AUTOSAR XML (schema 00048)
package /SecurityArchitecture/ComponentTypes
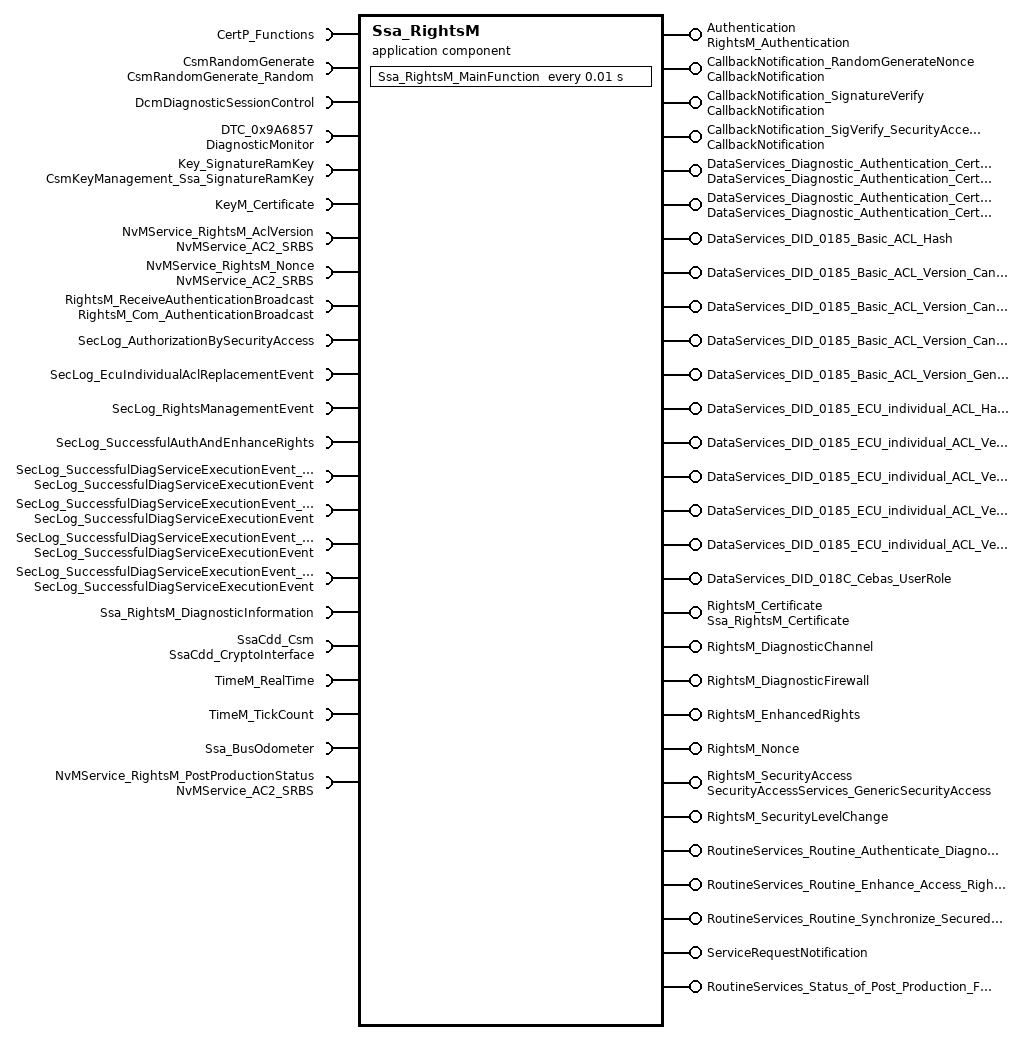
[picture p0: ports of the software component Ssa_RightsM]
  application sw component type Ssa_RightsM  # Handles a received diagnostic authentication broadcast and enters authenticated state if valid. Called by Ssa_BcTp whenever a Diagnostic Authentication broadcast message is received.
    28 x provide port:
      Authentication: mode-switch-sender-com-spec{mode-group=Mode, queue-length=1}, provided-interface=RightsM_Authentication
      CallbackNotification_RandomGenerateNonce: server-com-spec{operation=CallbackNotification, queue-length=1}, provided-interface=CallbackNotification  # Callback notification from the CSM random generate job. Configuration Variant(s): Asynchronous job processing.
      CallbackNotification_SignatureVerify: server-com-spec{operation=CallbackNotification, queue-length=1}, provided-interface=CallbackNotification  # Callback notification from the CSM signature verification job used for verifying the proof of ownership during diagnostic tester authentication. Configuration Variant(s): Asynchronous job processing.
      CallbackNotification_SigVerify_SecurityAccess: server-com-spec{operation=CallbackNotification, queue-length=1}, provided-interface=CallbackNotification  # Callback notification from the CSM signature verification job used for the security access. Configuration Variant(s): Asynchronous job processing.
      DataServices_Diagnostic_Authentication_Certificate_Identification_Read_Issuer: provided-com-specs=[{operation=ConditionCheckRead, queue-length=1}, {operation=ReadData, queue-length=1}], provided-interface=DataServices_Diagnostic_Authentication_Certificate_Identification_Read_Diagnostic_Authentication_Certificate_Issuer  # Reads issuer of current diagnostic authentication certificate and pass it to given data parameter. Connect to corresponding Dcm port.
      DataServices_Diagnostic_Authentication_Certificate_Identification_Read_Serial_Number: provided-interface=DataServices_Diagnostic_Authentication_Certificate_Identification_Read_Diagnostic_Authentication_Certificate_Serial_Number  # Reads serial number of current diagnostic authentication certificate and pass it to given data parameter. Connect to corresponding Dcm port.
        provided-com-specs:
          operation=ConditionCheckRead, queue-length=1
          operation=ReadData, queue-length=1
          operation=ReadDataLength, queue-length=1
      DataServices_DID_0185_Basic_ACL_Hash: provided-com-specs=[{operation=ConditionCheckRead, queue-length=1}, {operation=ReadData, queue-length=1}], provided-interface=DataServices_DID_0185_Basic_ACL_Hash
      DataServices_DID_0185_Basic_ACL_Version_Candela_File_Version_Major: provided-com-specs=[{operation=ConditionCheckRead, queue-length=1}, {operation=ReadData, queue-length=1}], provided-interface=DataServices_DID_0185_Basic_ACL_Version_Candela_File_Version_Major
      DataServices_DID_0185_Basic_ACL_Version_Candela_File_Version_Minor: provided-com-specs=[{operation=ConditionCheckRead, queue-length=1}, {operation=ReadData, queue-length=1}], provided-interface=DataServices_DID_0185_Basic_ACL_Version_Candela_File_Version_Minor
      DataServices_DID_0185_Basic_ACL_Version_Candela_File_Version_Patch: provided-com-specs=[{operation=ConditionCheckRead, queue-length=1}, {operation=ReadData, queue-length=1}], provided-interface=DataServices_DID_0185_Basic_ACL_Version_Candela_File_Version_Patch
      DataServices_DID_0185_Basic_ACL_Version_Generation_Time_GTC: provided-com-specs=[{operation=ConditionCheckRead, queue-length=1}, {operation=ReadData, queue-length=1}], provided-interface=DataServices_DID_0185_Basic_ACL_Version_Generation_Time_GTC
      DataServices_DID_0185_ECU_individual_ACL_Hash: provided-com-specs=[{operation=ConditionCheckRead, queue-length=1}, {operation=ReadData, queue-length=1}], provided-interface=DataServices_DID_0185_ECU_individual_ACL_Hash
      DataServices_DID_0185_ECU_individual_ACL_Version_Candela_File_Version_Major: provided-com-specs=[{operation=ConditionCheckRead, queue-length=1}, {operation=ReadData, queue-length=1}], provided-interface=DataServices_DID_0185_ECU_individual_ACL_Version_Candela_File_Version_Major
      DataServices_DID_0185_ECU_individual_ACL_Version_Candela_File_Version_Minor: provided-com-specs=[{operation=ConditionCheckRead, queue-length=1}, {operation=ReadData, queue-length=1}], provided-interface=DataServices_DID_0185_ECU_individual_ACL_Version_Candela_File_Version_Minor
      DataServices_DID_0185_ECU_individual_ACL_Version_Candela_File_Version_Patch: provided-com-specs=[{operation=ConditionCheckRead, queue-length=1}, {operation=ReadData, queue-length=1}], provided-interface=DataServices_DID_0185_ECU_individual_ACL_Version_Candela_File_Version_Patch
      DataServices_DID_0185_ECU_individual_ACL_Version_Generation_Time_GTC: provided-com-specs=[{operation=ConditionCheckRead, queue-length=1}, {operation=ReadData, queue-length=1}], provided-interface=DataServices_DID_0185_ECU_individual_ACL_Version_Generation_Time_GTC
      DataServices_DID_018C_Cebas_UserRole: provided-com-specs=[{operation=ConditionCheckRead, queue-length=1}, {operation=ReadData, queue-length=1}], provided-interface=DataServices_DID_018C_Cebas_UserRole
      RightsM_Certificate: server-com-spec{operation=GetDiagAuthCertSerialNumber_SecurityAccess, queue-length=1}, provided-interface=Ssa_RightsM_Certificate
      RightsM_DiagnosticChannel: provided-interface=RightsM_DiagnosticChannel
        provided-com-specs:
          operation=GetDiagChanAndAuthStatus, queue-length=1
          operation=GetDiagnosticUserRole, queue-length=1
          operation=GetDiagnosticUserRolesBitMask, queue-length=1
          operation=GetPostProductionStatus, queue-length=1
      RightsM_DiagnosticFirewall: provided-interface=RightsM_DiagnosticFirewall
        provided-com-specs:
          operation=GetDiagnosticUserRole, queue-length=1
          operation=IsEnhancedAccessRightGranted, queue-length=1
      RightsM_EnhancedRights: server-com-spec{operation=VerifySubjectKeyIdentifier, queue-length=1}, provided-interface=RightsM_EnhancedRights
      RightsM_Nonce: provided-com-specs=[{operation=Destroy, queue-length=1}, {operation=Get, queue-length=1}], provided-interface=RightsM_Nonce
      RightsM_SecurityAccess: provided-com-specs=[{operation=CompareKey, queue-length=1}, {operation=GetSeed, queue-length=1}], provided-interface=SecurityAccessServices_GenericSecurityAccess
      RightsM_SecurityLevelChange: nonqueued-sender-com-spec{data-element=currentLevel, init-value=0}, provided-interface=RightsM_SecurityLevelChange
      RoutineServices_Routine_Authenticate_Diagnostic_User_or_Tester: server-com-spec{operation=Start, queue-length=1}, provided-interface=RoutineServices_Routine_Authenticate_Diagnostic_User_or_Tester  # Authenticate a diagnostic user or tester against the ECU to obtain the appropriate access rights (authorization).
      RoutineServices_Routine_Enhance_Access_Rights: server-com-spec{operation=Start, queue-length=1}, provided-interface=RoutineServices_Routine_Enhance_Access_Rights  # Request further access rights beyond the ones which are granted by the authentication of the diagnostic test tool.
      RoutineServices_Routine_Synchronize_Secured_System_Date_and_Time: server-com-spec{operation=Start, queue-length=1}, provided-interface=RoutineServices_Routine_Synchronize_Secured_System_Date_and_Time  # Initiate time synchronization by requesting a one-time challenge (nonce).
      ServiceRequestNotification: provided-com-specs=[{operation=Confirmation, queue-length=1}, {operation=Indication, queue-length=1}], provided-interface=ServiceRequestNotification  # Checks the access rights of the incoming diagnostic request for the currently authenticated user role. If not granted, request will be aborted! Connect to corresponding Dcm port.
    22 x require port:
      CertP_Functions: required-interface=CertP_Functions
        required-com-specs:
          AttributeCertificate_Parse
          Certificate_Compare
          Certificate_Parse
          Certificate_Verify
          Certificate_Verify_Extended
          ParseTime
      CsmRandomGenerate: client-com-spec=RandomGenerate, required-interface=CsmRandomGenerate_Random  # Generates a random number. Connect to a Csm Random job.
      DcmDiagnosticSessionControl: mode-switch-receiver-com-spec{enhanced-mode-api=true, mode-group=DcmDiagnosticSessionControl}, required-interface=DcmDiagnosticSessionControl  # Receives the current diagnostic session of dcm. Connect to corresponding Dcm port.
      DTC_0x9A6857: required-com-specs=[ResetEventDebounceStatus, ResetEventStatus, SetEventStatus], required-interface=DiagnosticMonitor  # Set a Event Status to failed if a new AccessControlList does not match to the ECU's Diagnostic Variant and Diagnostic Version. Connect to corresponding event of Dem.
      Key_SignatureRamKey: required-com-specs=[KeyElementGet, KeyElementSet, KeySetValid], required-interface=CsmKeyManagement_Ssa_SignatureRamKey  # Sets the public key of a certificate to verify data signed by this certificate. Connect to a Csm Key which is able to store a public key and is used in job of port CsmSignatureVerify.
      KeyM_Certificate: required-interface=KeyM_Certificate
        required-com-specs:
          GetBackendSerialNumber
          GetBackendSubject
          VerifyCertWithBackendCert
          SignData4092ByteWithEcuPrivateKey
          VerifyCertWithBackendCert
          SignData1024ByteWithEcuPrivateKey
          CheckTrustModelChainOfTrust
      NvMService_RightsM_AclVersion: required-com-specs=[GetErrorStatus, ReadBlock, SetRamBlockStatus, WriteBlock], required-interface=NvMService_AC2_SRBS  # Controlling the NvM block which stores the version of the ECU individual ACL. Connect to NvM block storing the version of the ECU individual ACL.
      NvMService_RightsM_Nonce: required-com-specs=[GetErrorStatus, ReadBlock, SetRamBlockStatus, WriteBlock], required-interface=NvMService_AC2_SRBS  # Controlling the NvM block which stores the nonce generated and used during synchronizing the secured system date and time or during distribution of the car-specific secert at the garage or dealerships. Connect to NvM block storing this nonce.
      RightsM_ReceiveAuthenticationBroadcast: nonqueued-receiver-com-spec{data-element=authentication, filter=data-filter-type=ALWAYS, init-value=constant-reference=Ssa_Init_Zero_20Byte}, required-interface=RightsM_Com_AuthenticationBroadcast  # Configuration Variant(s): Not in VSM.
      SecLog_AuthorizationBySecurityAccess: client-com-spec=AuthorizationBySecurityAccess, required-interface=SecLog_AuthorizationBySecurityAccess
      SecLog_EcuIndividualAclReplacementEvent: client-com-spec=EcuIndividualAclReplacement, required-interface=SecLog_EcuIndividualAclReplacementEvent
      SecLog_RightsManagementEvent: client-com-spec=RightsManagement, required-interface=SecLog_RightsManagementEvent
      SecLog_SuccessfulAuthAndEnhanceRights: client-com-spec=SuccessfulAuthAndEnhanceRights, required-interface=SecLog_SuccessfulAuthAndEnhanceRights
      SecLog_SuccessfulDiagServiceExecutionEvent_ActivateDebugIf: client-com-spec=SuccessfulDiagServiceExecution, required-interface=SecLog_SuccessfulDiagServiceExecutionEvent
      SecLog_SuccessfulDiagServiceExecutionEvent_ClearSarMemory: client-com-spec=SuccessfulDiagServiceExecution, required-interface=SecLog_SuccessfulDiagServiceExecutionEvent
      SecLog_SuccessfulDiagServiceExecutionEvent_EnableSarMemOverwrite: client-com-spec=SuccessfulDiagServiceExecution, required-interface=SecLog_SuccessfulDiagServiceExecutionEvent
      SecLog_SuccessfulDiagServiceExecutionEvent_EraseMemory: client-com-spec=SuccessfulDiagServiceExecution, required-interface=SecLog_SuccessfulDiagServiceExecutionEvent
      Ssa_RightsM_DiagnosticInformation: client-com-spec=Get, required-interface=Ssa_RightsM_DiagnosticInformation
      SsaCdd_Csm: required-com-specs=[CancelJob, SignatureVerify, SignatureGenerate, SignatureVerify, Hash], required-interface=SsaCdd_CryptoInterface
      TimeM_RealTime: required-com-specs=[Compare, Get, Set], required-interface=TimeM_RealTime
      TimeM_TickCount: client-com-spec=Get, required-interface=TimeM_TickCount
      Ssa_BusOdometer: nonqueued-receiver-com-spec{data-element=DI_Odo_Pr5_ST3, end-to-end-transformation-com-spec-props=disable-end-to-end-check=true, filter=data-filter-type=ALWAYS, init-value=constant-reference=Ssa_Init_BusOdometerRecord}, required-interface=Ssa_BusOdometer  # This port receives the mileage value.
    provide port RoutineServices_Status_of_Post_Production_Flag: provided-interface=RoutineServices_Status_of_Post_Production_Flag  # Controls and returns the Post Production Status. Connect to corresponding Dcm port.
      provided-com-specs:
        operation=RequestResults, queue-length=1
        operation=Start, queue-length=1
        operation=Stop, queue-length=1
    require port NvMService_RightsM_PostProductionStatus: required-com-specs=[GetErrorStatus, ReadBlock, SetRamBlockStatus, WriteBlock], required-interface=NvMService_AC2_SRBS  # Controlling the NvM block which stores the post production status. Connect to NvM block storing the post production status.
    behavior Ssa_RightsM_InternalBehavior: data-type-mapping=SSATypeMappingSet, included-data-type-set=data-type=[RightsM_ACL_BitMaskType, RightsM_AuthenticationBroadcastType, RightsM_AuthenticationModeType, RightsM_AuthenticationStateType, RightsM_DiagChannelDataType, RightsM_DiagnosticUserRoleType, RightsM_NonceType, Ssa_KeyElementType]
      exclusive area RightsM_ExclusiveArea
      ar-typed-per-instance-memorys:
        6 x data:
          RightsMAclVersion: type=SecLog_AclVersionType
          RightsMNonce: type=RightsM_NonceType
          RightsMNonceMirror: type=RightsM_NonceType
          RightsMPostProductionStatus: type=Ssa_PostProductionStatusType
          RightsMPostProductionStatusMirror: type=Ssa_PostProductionStatusType
          RightsMPostProductionStatusMirror2: type=Ssa_PostProductionStatusType
      operation invoked event OIT_RightsM_Certificate_GetDiagAuthCertSerialNumber_SecurityAccess_RightsM_Certificate_GetDiagAuthCertSerialNumber_SecurCA0CC351: start-on-event=Ssa_RightsM_Certificate_GetDiagAuthCertSerialNumber_SecurityAccess, operation=RightsM_Certificate.GetDiagAuthCertSerialNumber_SecurityAccess
      data received event DRT_RightsM_Com_BroadcastAuthentification_RightsM_ReceiveAuthenticationBroadcast_authentication: start-on-event=Ssa_RightsM_Com_ReceiveBroadcastAuthentication, data=RightsM_ReceiveAuthenticationBroadcast.authentication
      34 x operation invoked event:
        OIT_CallbackNotification_RandomGenerateNonce_CallbackNotification_CallbackNotification_RandomGenerateNonce_CallbackNotification: start-on-event=Ssa_RightsM_CsmCallbackNotification_RandomGenerate, operation=CallbackNotification_RandomGenerateNonce.CallbackNotification
        OIT_CallbackNotification_SignatureVerify_CallbackNotification_CallbackNotification_SignatureVerify_CallbackNotification: start-on-event=Ssa_RightsM_CsmCallbackNotification_SignatureVerify, operation=CallbackNotification_SignatureVerify.CallbackNotification
        OIT_Ssa_RightsM_CallbackNotification_SigVerify_SecurityAccess_CallbackNotification_CallbackNotification_SigVerify_Securi5261B0AF: start-on-event=Ssa_RightsM_CsmCallbackNotification_SigVerify_SecurityAccess, operation=CallbackNotification_SigVerify_SecurityAccess.CallbackNotification
        OIT_RightsM_DataServices_Diagnostic_Authentication_Certificate_Identification_Read_Issuer_ConditionCheckRead_DataService680336B6: start-on-event=Ssa_RightsM_DataServices_Diagnostic_Authentication_Certificate_Identification_Read_Issuer_ConditionCheckRead, operation=DataServices_Diagnostic_Authentication_Certificate_Identification_Read_Issuer.ConditionCheckRead
        OIT_RightsM_DataServices_Diagnostic_Authentication_Certificate_Identification_Read_Issuer_ReadData_DataServices_DiagnostD20AFA95: start-on-event=Ssa_RightsM_DataServices_Diagnostic_Authentication_Certificate_Identification_Read_Issuer_ReadData, operation=DataServices_Diagnostic_Authentication_Certificate_Identification_Read_Issuer.ReadData
        OIT_RightsM_DataServices_Diagnostic_Authentication_Certificate_Identification_Read_Serial_Number_ConditionCheckRead_Data9DF07878: start-on-event=Ssa_RightsM_DataServices_Diagnostic_Authentication_Certificate_Identification_Read_Serial_Number_ConditionCheckRead, operation=DataServices_Diagnostic_Authentication_Certificate_Identification_Read_Serial_Number.ConditionCheckRead
        OIT_RightsM_DataServices_Diagnostic_Authentication_Certificate_Identification_Read_Serial_Number_ReadData_DataServices_D5784EB7D: start-on-event=Ssa_RightsM_DataServices_Diagnostic_Authentication_Certificate_Identification_Read_Serial_Number_ReadData, operation=DataServices_Diagnostic_Authentication_Certificate_Identification_Read_Serial_Number.ReadData
        OIT_RightsM_DataServices_Diagnostic_Authentication_Certificate_Identification_Read_Serial_Number_ReadDataLength_DataServ9E028842: start-on-event=Ssa_RightsM_DataServices_Diagnostic_Authentication_Certificate_Identification_Read_Serial_Number_ReadDataLength, operation=DataServices_Diagnostic_Authentication_Certificate_Identification_Read_Serial_Number.ReadDataLength
        OIT_DataServices_DID_0185_Basic_ACL_Hash_ConditionCheckRead_DataServices_DID_0185_Basic_ACL_Hash_ConditionCheckRead: start-on-event=Ssa_RightsM_DataServices_DID_0185_Basic_ACL_Hash_ConditionCheckRead, operation=DataServices_DID_0185_Basic_ACL_Hash.ConditionCheckRead
        OIT_DataServices_DID_0185_Basic_ACL_Hash_ReadData_DataServices_DID_0185_Basic_ACL_Hash_ReadData: start-on-event=Ssa_RightsM_DataServices_DID_0185_Basic_ACL_Hash_ReadData, operation=DataServices_DID_0185_Basic_ACL_Hash.ReadData
        OIT_DataServices_DID_0185_Basic_ACL_Version_Candela_File_Version_Major_ConditionCheckRead_DataServices_DID_0185_Basic_AC92A58D88: start-on-event=Ssa_RightsM_DataServices_DID_0185_Basic_ACL_Version_Candela_File_Version_Major_ConditionCheckRead, operation=DataServices_DID_0185_Basic_ACL_Version_Candela_File_Version_Major.ConditionCheckRead
        OIT_DataServices_DID_0185_Basic_ACL_Version_Candela_File_Version_Major_ReadData_DataServices_DID_0185_Basic_ACL_Version_77015D53: start-on-event=Ssa_RightsM_DataServices_DID_0185_Basic_ACL_Version_Candela_File_Version_Major_ReadData, operation=DataServices_DID_0185_Basic_ACL_Version_Candela_File_Version_Major.ReadData
        OIT_DataServices_DID_0185_Basic_ACL_Version_Candela_File_Version_Minor_ConditionCheckRead_DataServices_DID_0185_Basic_ACFC22C779: start-on-event=Ssa_RightsM_DataServices_DID_0185_Basic_ACL_Version_Candela_File_Version_Minor_ConditionCheckRead, operation=DataServices_DID_0185_Basic_ACL_Version_Candela_File_Version_Minor.ConditionCheckRead
        OIT_DataServices_DID_0185_Basic_ACL_Version_Candela_File_Version_Minor_ReadData_DataServices_DID_0185_Basic_ACL_Version_3D61F3A6: start-on-event=Ssa_RightsM_DataServices_DID_0185_Basic_ACL_Version_Candela_File_Version_Minor_ReadData, operation=DataServices_DID_0185_Basic_ACL_Version_Candela_File_Version_Minor.ReadData
        OIT_DataServices_DID_0185_Basic_ACL_Version_Candela_File_Version_Patch_ConditionCheckRead_DataServices_DID_0185_Basic_ACA122FA4A: start-on-event=Ssa_RightsM_DataServices_DID_0185_Basic_ACL_Version_Candela_File_Version_Patch_ConditionCheckRead, operation=DataServices_DID_0185_Basic_ACL_Version_Candela_File_Version_Patch.ConditionCheckRead
        OIT_DataServices_DID_0185_Basic_ACL_Version_Candela_File_Version_Patch_ReadData_DataServices_DID_0185_Basic_ACL_Version_F21521B5: start-on-event=Ssa_RightsM_DataServices_DID_0185_Basic_ACL_Version_Candela_File_Version_Patch_ReadData, operation=DataServices_DID_0185_Basic_ACL_Version_Candela_File_Version_Patch.ReadData
        OIT_DataServices_DID_0185_Basic_ACL_Version_Generation_Time_GTC_ConditionCheckRead_DataServices_DID_0185_Basic_ACL_Versi5543092B: start-on-event=Ssa_RightsM_DataServices_DID_0185_Basic_ACL_Version_Generation_Time_GTC_ConditionCheckRead, operation=DataServices_DID_0185_Basic_ACL_Version_Generation_Time_GTC.ConditionCheckRead
        OIT_DataServices_DID_0185_Basic_ACL_Version_Generation_Time_GTC_ReadData_DataServices_DID_0185_Basic_ACL_Version_GeneratCB1F4853: start-on-event=Ssa_RightsM_DataServices_DID_0185_Basic_ACL_Version_Generation_Time_GTC_ReadData, operation=DataServices_DID_0185_Basic_ACL_Version_Generation_Time_GTC.ReadData
        OIT_DataServices_DID_0185_ECU_indvidual_ACL_Hash_ConditionCheckRead_DataServices_DID_0185_ECU_indvidual_ACL_Hash_ConditiBD3D90BE: start-on-event=Ssa_RightsM_DataServices_DID_0185_ECU_individual_ACL_Hash_ConditionCheckRead, operation=DataServices_DID_0185_ECU_individual_ACL_Hash.ConditionCheckRead
        OIT_DataServices_DID_0185_ECU_indvidual_ACL_Hash_ReadData_DataServices_DID_0185_ECU_indvidual_ACL_Hash_ReadData: start-on-event=Ssa_RightsM_DataServices_DID_0185_ECU_individual_ACL_Hash_ReadData, operation=DataServices_DID_0185_ECU_individual_ACL_Hash.ReadData
        OIT_DataServices_DID_0185_ECU_indvidual_ACL_Version_Candela_File_Version_Major_ConditionCheckRead_DataServices_DID_0185_FE41219E: start-on-event=Ssa_RightsM_DataServices_DID_0185_ECU_individual_ACL_Version_Candela_File_Version_Major_ConditionCheckRead, operation=DataServices_DID_0185_ECU_individual_ACL_Version_Candela_File_Version_Major.ConditionCheckRead
        OIT_DataServices_DID_0185_ECU_indvidual_ACL_Version_Candela_File_Version_Major_ReadData_DataServices_DID_0185_ECU_indvidA5B8BE16: start-on-event=Ssa_RightsM_DataServices_DID_0185_ECU_individual_ACL_Version_Candela_File_Version_Major_ReadData, operation=DataServices_DID_0185_ECU_individual_ACL_Version_Candela_File_Version_Major.ReadData
        OIT_DataServices_DID_0185_ECU_indvidual_ACL_Version_Candela_File_Version_Minor_ConditionCheckRead_DataServices_DID_0185_D2E8E8BF: start-on-event=Ssa_RightsM_DataServices_DID_0185_ECU_individual_ACL_Version_Candela_File_Version_Minor_ConditionCheckRead, operation=DataServices_DID_0185_ECU_individual_ACL_Version_Candela_File_Version_Minor.ConditionCheckRead
        OIT_DataServices_DID_0185_ECU_indvidual_ACL_Version_Candela_File_Version_Minor_ReadData_DataServices_DID_0185_ECU_indvid2D0A4984: start-on-event=Ssa_RightsM_DataServices_DID_0185_ECU_individual_ACL_Version_Candela_File_Version_Minor_ReadData, operation=DataServices_DID_0185_ECU_individual_ACL_Version_Candela_File_Version_Minor.ReadData
        OIT_DataServices_DID_0185_ECU_indvidual_ACL_Version_Candela_File_Version_Patch_ConditionCheckRead_DataServices_DID_0185_FE0DA8D4: start-on-event=Ssa_RightsM_DataServices_DID_0185_ECU_individual_ACL_Version_Candela_File_Version_Patch_ConditionCheckRead, operation=DataServices_DID_0185_ECU_individual_ACL_Version_Candela_File_Version_Patch.ConditionCheckRead
        OIT_DataServices_DID_0185_ECU_indvidual_ACL_Version_Candela_File_Version_Patch_ReadData_DataServices_DID_0185_ECU_indvid5A9554C0: start-on-event=Ssa_RightsM_DataServices_DID_0185_ECU_individual_ACL_Version_Candela_File_Version_Patch_ReadData, operation=DataServices_DID_0185_ECU_individual_ACL_Version_Candela_File_Version_Patch.ReadData
        OIT_DataServices_DID_0185_ECU_indvidual_ACL_Version_Generation_Time_GTC_ConditionCheckRead_DataServices_DID_0185_ECU_ind65A56DF2: start-on-event=Ssa_RightsM_DataServices_DID_0185_ECU_individual_ACL_Version_Generation_Time_GTC_ConditionCheckRead, operation=DataServices_DID_0185_ECU_individual_ACL_Version_Generation_Time_GTC.ConditionCheckRead
        OIT_DataServices_DID_0185_ECU_indvidual_ACL_Version_Generation_Time_GTC_ReadData_DataServices_DID_0185_ECU_indvidual_ACL0234A191: start-on-event=Ssa_RightsM_DataServices_DID_0185_ECU_individual_ACL_Version_Generation_Time_GTC_ReadData, operation=DataServices_DID_0185_ECU_individual_ACL_Version_Generation_Time_GTC.ReadData
        OIT_DataServices_DID_018C_Cebas_UserRole_ConditionCheckRead_DataServices_DID_018C_Cebas_UserRole_ConditionCheckRead: start-on-event=Ssa_RightsM_DataServices_DID_018C_Cebas_UserRole_ConditionCheckRead, operation=DataServices_DID_018C_Cebas_UserRole.ConditionCheckRead
        OIT_DataServices_DID_018C_Cebas_UserRole_ReadData_DataServices_DID_018C_Cebas_UserRole_ReadData: start-on-event=Ssa_RightsM_DataServices_DID_018C_Cebas_UserRole_ReadData, operation=DataServices_DID_018C_Cebas_UserRole.ReadData
        OIT_RightsM_DiagnosticChannel_GetDiagChanAndAuthenticationState_RightsM_DiagnosticChannel_GetDiagChanAndAuthenticationState: start-on-event=Ssa_RightsM_DiagnosticChannel_GetDiagChanAndAuthenticationState, operation=RightsM_DiagnosticChannel.GetDiagChanAndAuthStatus
        OIT_Ssa_RightsM_DiagnosticChannel_GetDiagnosticUserRolesBitMask_RightsM_DiagnosticChannel_GetDiagnosticUserRolesBitMask: start-on-event=Ssa_RightsM_DiagnosticChannel_GetDiagnosticUserRolesBitMask, operation=RightsM_DiagnosticChannel.GetDiagnosticUserRolesBitMask
        OIT_RightsM_DiagnosticFirewall_GetDiagnosticUserRole_RightsM_DiagnosticFirewall_GetDiagnosticUserRole: start-on-event=Ssa_RightsM_DiagnosticFirewall_GetDiagnosticUserRole, operation=RightsM_DiagnosticFirewall.GetDiagnosticUserRole
        OIT_RightsM_DiagnosticFirewall_IsEnhancedAccessRightGranted_RightsM_DiagnosticFirewall_IsEnhancedAccessRightGranted: start-on-event=Ssa_RightsM_DiagnosticFirewall_IsEnhancedAccessRightGranted, operation=RightsM_DiagnosticFirewall.IsEnhancedAccessRightGranted
      swc mode switch event MST_Ssa_RightsM_DiagnosticSessionChangeIndication_0: start-on-event=Ssa_RightsM_DiagnosticSessionChangeIndication, activation=ON-ENTRY, mode=DcmDiagnosticSessionControl.DcmDiagnosticSessionControl.DEFAULT_SESSION
      swc mode switch event MST_Ssa_RightsM_DiagnosticSessionChangeIndication_1: start-on-event=Ssa_RightsM_DiagnosticSessionChangeIndication, activation=ON-ENTRY, mode=DcmDiagnosticSessionControl.DcmDiagnosticSessionControl.EXTENDED_SESSION
      operation invoked event OIT_RightsM_EnhancedRights_VerifySubjectKeyIdentifier_RightsM_EnhancedRights_VerifySubjectKeyIdentifier: start-on-event=Ssa_RightsM_EnhancedRights_VerifySubjectKeyIdentifier, operation=RightsM_EnhancedRights.VerifySubjectKeyIdentifier
      init event RightsM_InitEvent: start-on-event=Ssa_RightsM_Init
      timing event TMT_RightsM_MainFunction: start-on-event=Ssa_RightsM_MainFunction, period=0.01
      14 x operation invoked event:
        OIT_RightsM_Nonce_Destroy_RightsM_Nonce_Destroy: start-on-event=Ssa_RightsM_Nonce_Destroy, operation=RightsM_Nonce.Destroy
        OIT_RightsM_Nonce_Get_RightsM_Nonce_Get: start-on-event=Ssa_RightsM_Nonce_Get, operation=RightsM_Nonce.Get
        OIT_Ssa_RightsM_RoutineServices_Routine_Authenticate_Diagnostic_User_or_Tester_Start_RoutineServices_Routine_AuthenticatE1C9718B: start-on-event=Ssa_RightsM_RoutineServices_Routine_Authenticate_Diagnostic_User_or_Tester_Start, operation=RoutineServices_Routine_Authenticate_Diagnostic_User_or_Tester.Start
        OIT_Ssa_RightsM_RoutineServices_Routine_Enhance_Access_Rights_Start_RoutineServices_Routine_Enhance_Access_Rights_Start_1: start-on-event=Ssa_RightsM_RoutineServices_Routine_Enhance_Access_Rights_Start, operation=RoutineServices_Routine_Enhance_Access_Rights.Start
        OIT_Ssa_RightsM_RoutineServices_Routine_Synchronize_Secured_System_Date_and_Time_Start_RoutineServices_Routine_SynchroniEDFF1183: start-on-event=Ssa_RightsM_RoutineServices_Routine_Synchronize_Secured_System_Date_and_Time_Start, operation=RoutineServices_Routine_Synchronize_Secured_System_Date_and_Time.Start
        OIT_RightsM_SecurityAccess_CompareKey_RightsM_SecurityAccess_CompareKey: start-on-event=Ssa_RightsM_SecurityAccess_CompareKey, operation=RightsM_SecurityAccess.CompareKey
        OIT_RightsM_SecurityAccess_GetSeed_RightsM_SecurityAccess_GetSeed: start-on-event=Ssa_RightsM_SecurityAccess_GetSeed, operation=RightsM_SecurityAccess.GetSeed
        OIT_RightsM_ServiceRequestNotification_Confirmation_ServiceRequestNotification_Confirmation: start-on-event=Ssa_RightsM_ServiceRequestNotification_Confirmation, operation=ServiceRequestNotification.Confirmation
        OIT_RightsM_ServiceRequestNotification_Indication_ServiceRequestNotification_Indication: start-on-event=Ssa_RightsM_ServiceRequestNotification_Indication, operation=ServiceRequestNotification.Indication
        OIT_Ssa_RightsM_DiagnosticChannel_GetDiagnosticUserRole_RightsM_DiagnosticChannel_GetDiagnosticUserRole: start-on-event=Ssa_RightsM_DiagnosticChannel_GetDiagnosticUserRole, operation=RightsM_DiagnosticChannel.GetDiagnosticUserRole
        OIT_RightsM_DiagnosticChannel_GetPostProductionStatus_RightsM_DiagnosticChannel_GetPostProductionStatus: start-on-event=Ssa_RightsM_DiagnosticChannel_GetPostProductionStatus, operation=RightsM_DiagnosticChannel.GetPostProductionStatus
        OIT_Ssa_RightsM_RoutineServices_Status_of_Post_Production_Flag_RequestResults_RoutineServices_Status_of_Post_Production_836576EC: start-on-event=Ssa_RightsM_RoutineServices_Status_of_Post_Production_Flag_RequestResults, operation=RoutineServices_Status_of_Post_Production_Flag.RequestResults
        OIT_Ssa_RightsM_RoutineServices_Status_of_Post_Production_Flag_Start_RoutineServices_Status_of_Post_Production_Flag_Start: start-on-event=Ssa_RightsM_RoutineServices_Status_of_Post_Production_Flag_Start, operation=RoutineServices_Status_of_Post_Production_Flag.Start
        OIT_Ssa_RightsM_RoutineServices_Status_of_Post_Production_Flag_Stop_RoutineServices_Status_of_Post_Production_Flag_Stop: start-on-event=Ssa_RightsM_RoutineServices_Status_of_Post_Production_Flag_Stop, operation=RoutineServices_Status_of_Post_Production_Flag.Stop
      port-api-options:
        enable-take-address=false, error-handling=NO-TRANSFORMER-ERROR-HANDLING, indirect-api=false, port=Authentication
        enable-take-address=false, error-handling=NO-TRANSFORMER-ERROR-HANDLING, indirect-api=false, port=CallbackNotification_SignatureVerify
        enable-take-address=false, error-handling=NO-TRANSFORMER-ERROR-HANDLING, indirect-api=false, port=CertP_Functions
        enable-take-address=false, error-handling=NO-TRANSFORMER-ERROR-HANDLING, indirect-api=false, port=CsmRandomGenerate
        enable-take-address=false, error-handling=NO-TRANSFORMER-ERROR-HANDLING, indirect-api=false, port=DataServices_Diagnostic_Authentication_Certificate_Identification_Read_Issuer
        enable-take-address=false, error-handling=NO-TRANSFORMER-ERROR-HANDLING, indirect-api=false, port=DataServices_Diagnostic_Authentication_Certificate_Identification_Read_Serial_Number
        enable-take-address=false, error-handling=NO-TRANSFORMER-ERROR-HANDLING, indirect-api=false, port=DataServices_DID_0185_Basic_ACL_Hash
        enable-take-address=false, error-handling=NO-TRANSFORMER-ERROR-HANDLING, indirect-api=false, port=DataServices_DID_0185_Basic_ACL_Version_Candela_File_Version_Major
        enable-take-address=false, error-handling=NO-TRANSFORMER-ERROR-HANDLING, indirect-api=false, port=DataServices_DID_0185_Basic_ACL_Version_Candela_File_Version_Minor
        enable-take-address=false, error-handling=NO-TRANSFORMER-ERROR-HANDLING, indirect-api=false, port=DataServices_DID_0185_Basic_ACL_Version_Candela_File_Version_Patch
        enable-take-address=false, error-handling=NO-TRANSFORMER-ERROR-HANDLING, indirect-api=false, port=DataServices_DID_0185_Basic_ACL_Version_Generation_Time_GTC
        enable-take-address=false, error-handling=NO-TRANSFORMER-ERROR-HANDLING, indirect-api=false, port=DataServices_DID_0185_ECU_individual_ACL_Hash
        enable-take-address=false, error-handling=NO-TRANSFORMER-ERROR-HANDLING, indirect-api=false, port=DataServices_DID_0185_ECU_individual_ACL_Version_Candela_File_Version_Major
        enable-take-address=false, error-handling=NO-TRANSFORMER-ERROR-HANDLING, indirect-api=false, port=DataServices_DID_0185_ECU_individual_ACL_Version_Candela_File_Version_Minor
        enable-take-address=false, error-handling=NO-TRANSFORMER-ERROR-HANDLING, indirect-api=false, port=DataServices_DID_0185_ECU_individual_ACL_Version_Candela_File_Version_Patch
        enable-take-address=false, error-handling=NO-TRANSFORMER-ERROR-HANDLING, indirect-api=false, port=DataServices_DID_0185_ECU_individual_ACL_Version_Generation_Time_GTC
        enable-take-address=false, error-handling=NO-TRANSFORMER-ERROR-HANDLING, indirect-api=false, port=DcmDiagnosticSessionControl
        enable-take-address=false, error-handling=NO-TRANSFORMER-ERROR-HANDLING, indirect-api=false, port=DTC_0x9A6857
        enable-take-address=false, error-handling=NO-TRANSFORMER-ERROR-HANDLING, indirect-api=false, port=Key_SignatureRamKey
        enable-take-address=false, error-handling=NO-TRANSFORMER-ERROR-HANDLING, indirect-api=false, port=KeyM_Certificate
        enable-take-address=false, error-handling=NO-TRANSFORMER-ERROR-HANDLING, indirect-api=false, port=NvMService_RightsM_Nonce
        enable-take-address=false, error-handling=NO-TRANSFORMER-ERROR-HANDLING, indirect-api=false, port=RightsM_DiagnosticChannel
        enable-take-address=false, error-handling=NO-TRANSFORMER-ERROR-HANDLING, indirect-api=false, port=RightsM_EnhancedRights
        enable-take-address=false, error-handling=NO-TRANSFORMER-ERROR-HANDLING, indirect-api=false, port=RightsM_Nonce
        enable-take-address=false, error-handling=NO-TRANSFORMER-ERROR-HANDLING, indirect-api=false, port=RightsM_ReceiveAuthenticationBroadcast
        enable-take-address=false, error-handling=NO-TRANSFORMER-ERROR-HANDLING, indirect-api=false, port=RightsM_SecurityAccess
        enable-take-address=false, error-handling=NO-TRANSFORMER-ERROR-HANDLING, indirect-api=false, port=RightsM_SecurityLevelChange
        enable-take-address=false, error-handling=NO-TRANSFORMER-ERROR-HANDLING, indirect-api=false, port=SecLog_AuthorizationBySecurityAccess
        enable-take-address=false, error-handling=NO-TRANSFORMER-ERROR-HANDLING, indirect-api=false, port=SecLog_EcuIndividualAclReplacementEvent
        enable-take-address=false, error-handling=NO-TRANSFORMER-ERROR-HANDLING, indirect-api=false, port=SecLog_RightsManagementEvent
        enable-take-address=false, error-handling=NO-TRANSFORMER-ERROR-HANDLING, indirect-api=false, port=SecLog_SuccessfulAuthAndEnhanceRights
        enable-take-address=false, error-handling=NO-TRANSFORMER-ERROR-HANDLING, indirect-api=false, port=SecLog_SuccessfulDiagServiceExecutionEvent_ActivateDebugIf
        enable-take-address=false, error-handling=NO-TRANSFORMER-ERROR-HANDLING, indirect-api=false, port=SecLog_SuccessfulDiagServiceExecutionEvent_ClearSarMemory
        enable-take-address=false, error-handling=NO-TRANSFORMER-ERROR-HANDLING, indirect-api=false, port=SecLog_SuccessfulDiagServiceExecutionEvent_EnableSarMemOverwrite
        enable-take-address=false, error-handling=NO-TRANSFORMER-ERROR-HANDLING, indirect-api=false, port=SecLog_SuccessfulDiagServiceExecutionEvent_EraseMemory
        enable-take-address=false, error-handling=NO-TRANSFORMER-ERROR-HANDLING, indirect-api=false, port=ServiceRequestNotification
        enable-take-address=false, error-handling=NO-TRANSFORMER-ERROR-HANDLING, indirect-api=false, port=Ssa_RightsM_DiagnosticInformation
        enable-take-address=false, error-handling=NO-TRANSFORMER-ERROR-HANDLING, indirect-api=false, port=SsaCdd_Csm
        enable-take-address=false, error-handling=NO-TRANSFORMER-ERROR-HANDLING, indirect-api=false, port=TimeM_RealTime
        enable-take-address=false, error-handling=NO-TRANSFORMER-ERROR-HANDLING, indirect-api=false, port=TimeM_TickCount
      54 x runnable:
        Ssa_RightsM_Certificate_GetDiagAuthCertSerialNumber_SecurityAccess: can-be-invoked-concurrently=true
        Ssa_RightsM_Com_ReceiveBroadcastAuthentication: can-enter-exclusive-area=RightsM_ExclusiveArea  # Called by Com when Broadcast message from VSM is received. Configuration Variant(s): Not in VSM.
          data-receive-point-by-arguments:
            access REC_RightsM_ReceiveAuthenticationBroadcast_authentication: accessed-variable=RightsM_ReceiveAuthenticationBroadcast.authentication
          mode switch point SWITCH_Authentication_Mode: mode-group=Authentication.Mode
          sync call SC_KeyM_Certificate_GetBackendSerialNumber: operation=KeyM_Certificate.GetBackendSerialNumber
          sync call SC_SecLog_SuccessfulAuthAndEnhanceRights_SuccessfulAuthAndEnhanceRights: operation=SecLog_SuccessfulAuthAndEnhanceRights.SuccessfulAuthAndEnhanceRights
        Ssa_RightsM_CsmCallbackNotification_RandomGenerate  # Configuration Variant(s): Asynchronous job processing.
        Ssa_RightsM_CsmCallbackNotification_SignatureVerify  # Configuration Variant(s): Asynchronous job processing.
        Ssa_RightsM_CsmCallbackNotification_SigVerify_SecurityAccess: can-enter-exclusive-area=RightsM_ExclusiveArea  # Configuration Variant(s): Asynchronous job processing.
        Ssa_RightsM_DataServices_Diagnostic_Authentication_Certificate_Identification_Read_Issuer_ConditionCheckRead
        Ssa_RightsM_DataServices_Diagnostic_Authentication_Certificate_Identification_Read_Issuer_ReadData: can-enter-exclusive-area=RightsM_ExclusiveArea
          sync call SC_KeyM_Certificate_GetBackendSubject: operation=KeyM_Certificate.GetBackendSubject
        Ssa_RightsM_DataServices_Diagnostic_Authentication_Certificate_Identification_Read_Serial_Number_ConditionCheckRead
        Ssa_RightsM_DataServices_Diagnostic_Authentication_Certificate_Identification_Read_Serial_Number_ReadData: can-enter-exclusive-area=RightsM_ExclusiveArea
        Ssa_RightsM_DataServices_Diagnostic_Authentication_Certificate_Identification_Read_Serial_Number_ReadDataLength
        Ssa_RightsM_DataServices_DID_0185_Basic_ACL_Hash_ConditionCheckRead
        Ssa_RightsM_DataServices_DID_0185_Basic_ACL_Hash_ReadData
        Ssa_RightsM_DataServices_DID_0185_Basic_ACL_Version_Candela_File_Version_Major_ConditionCheckRead
        Ssa_RightsM_DataServices_DID_0185_Basic_ACL_Version_Candela_File_Version_Major_ReadData
        Ssa_RightsM_DataServices_DID_0185_Basic_ACL_Version_Candela_File_Version_Minor_ConditionCheckRead
        Ssa_RightsM_DataServices_DID_0185_Basic_ACL_Version_Candela_File_Version_Minor_ReadData
        Ssa_RightsM_DataServices_DID_0185_Basic_ACL_Version_Candela_File_Version_Patch_ConditionCheckRead
        Ssa_RightsM_DataServices_DID_0185_Basic_ACL_Version_Candela_File_Version_Patch_ReadData
        Ssa_RightsM_DataServices_DID_0185_Basic_ACL_Version_Generation_Time_GTC_ConditionCheckRead
        Ssa_RightsM_DataServices_DID_0185_Basic_ACL_Version_Generation_Time_GTC_ReadData
        Ssa_RightsM_DataServices_DID_0185_ECU_individual_ACL_Hash_ConditionCheckRead
        Ssa_RightsM_DataServices_DID_0185_ECU_individual_ACL_Hash_ReadData
        Ssa_RightsM_DataServices_DID_0185_ECU_individual_ACL_Version_Candela_File_Version_Major_ConditionCheckRead
        Ssa_RightsM_DataServices_DID_0185_ECU_individual_ACL_Version_Candela_File_Version_Major_ReadData
        Ssa_RightsM_DataServices_DID_0185_ECU_individual_ACL_Version_Candela_File_Version_Minor_ConditionCheckRead
        Ssa_RightsM_DataServices_DID_0185_ECU_individual_ACL_Version_Candela_File_Version_Minor_ReadData
        Ssa_RightsM_DataServices_DID_0185_ECU_individual_ACL_Version_Candela_File_Version_Patch_ConditionCheckRead
        Ssa_RightsM_DataServices_DID_0185_ECU_individual_ACL_Version_Candela_File_Version_Patch_ReadData
        Ssa_RightsM_DataServices_DID_0185_ECU_individual_ACL_Version_Generation_Time_GTC_ConditionCheckRead
        Ssa_RightsM_DataServices_DID_0185_ECU_individual_ACL_Version_Generation_Time_GTC_ReadData
        Ssa_RightsM_DataServices_DID_018C_Cebas_UserRole_ConditionCheckRead
        Ssa_RightsM_DataServices_DID_018C_Cebas_UserRole_ReadData: can-enter-exclusive-area=RightsM_ExclusiveArea
        Ssa_RightsM_DiagnosticChannel_GetDiagChanAndAuthenticationState: can-enter-exclusive-area=RightsM_ExclusiveArea, can-be-invoked-concurrently=true
        Ssa_RightsM_DiagnosticChannel_GetDiagnosticUserRolesBitMask: can-enter-exclusive-area=RightsM_ExclusiveArea
        Ssa_RightsM_DiagnosticFirewall_GetDiagnosticUserRole: can-enter-exclusive-area=RightsM_ExclusiveArea
        Ssa_RightsM_DiagnosticFirewall_IsEnhancedAccessRightGranted: can-enter-exclusive-area=RightsM_ExclusiveArea
        Ssa_RightsM_DiagnosticSessionChangeIndication: can-enter-exclusive-area=RightsM_ExclusiveArea, mode-access-point=DcmDiagnosticSessionControl.DcmDiagnosticSessionControl
          data-send-points:
            access SEND_RightsM_SecurityLevelChange_currentLevel: accessed-variable=RightsM_SecurityLevelChange.currentLevel
        Ssa_RightsM_EnhancedRights_VerifySubjectKeyIdentifier: can-enter-exclusive-area=RightsM_ExclusiveArea
        Ssa_RightsM_Init
          mode switch point SWITCH_Authentication_Mode: mode-group=Authentication.Mode
          4 x sync call:
            SC_DTC_0x9A6857_SetEventStatus: operation=DTC_0x9A6857.SetEventStatus
            SC_SecLog_EcuIndividualAclReplacementEvent_EcuIndividualAclReplacement: operation=SecLog_EcuIndividualAclReplacementEvent.EcuIndividualAclReplacement
            SC_Ssa_RightsM_DiagnosticInformation_Get: operation=Ssa_RightsM_DiagnosticInformation.Get
            SC_SsaCdd_Csm_Hash: operation=SsaCdd_Csm.Hash
        Ssa_RightsM_MainFunction: can-enter-exclusive-area=RightsM_ExclusiveArea, mode-access-point=DcmDiagnosticSessionControl.DcmDiagnosticSessionControl
          data-receive-point-by-arguments:
            access REC_Ssa_BusOdometer_BusOdometerRecord: accessed-variable=Ssa_BusOdometer.DI_Odo_Pr5_ST3
          mode switch point SWITCH_Authentication_Mode: mode-group=Authentication.Mode
          5 x sync call:
            SC_KeyM_Certificate_GetBackendSerialNumber: operation=KeyM_Certificate.GetBackendSerialNumber
            SC_NvMService_RightsM_AclVersion_GetErrorStatus: operation=NvMService_RightsM_AclVersion.GetErrorStatus
            SC_NvMService_RightsM_AclVersion_WriteBlock: operation=NvMService_RightsM_AclVersion.WriteBlock
            SC_NvMService_RightsM_Nonce_GetErrorStatus: operation=NvMService_RightsM_Nonce.GetErrorStatus
            SC_NvMService_RightsM_Nonce_WriteBlock: operation=NvMService_RightsM_Nonce.WriteBlock
        Ssa_RightsM_Nonce_Destroy: can-enter-exclusive-area=RightsM_ExclusiveArea
          sync call SC_CsmRandomGenerate_RandomGenerate: operation=CsmRandomGenerate.RandomGenerate
        Ssa_RightsM_Nonce_Get: can-enter-exclusive-area=RightsM_ExclusiveArea
          sync call SC_CsmRandomGenerate_RandomGenerate: operation=CsmRandomGenerate.RandomGenerate
          sync call SC_TimeM_TickCount_Get: operation=TimeM_TickCount.Get
        Ssa_RightsM_RoutineServices_Routine_Authenticate_Diagnostic_User_or_Tester_Start: can-enter-exclusive-area=RightsM_ExclusiveArea
          mode switch point SWITCH_Authentication_Mode: mode-group=Authentication.Mode
          10 x sync call:
            SC_CertP_Functions_CertP_Certificate_Parse: operation=CertP_Functions.Certificate_Parse
            SC_CsmRandomGenerate_RandomGenerate: operation=CsmRandomGenerate.RandomGenerate
            SC_Key_SigantureRamKey_KeyElementSet: operation=Key_SignatureRamKey.KeyElementSet
            SC_Key_SigantureRamKey_KeySetValid: operation=Key_SignatureRamKey.KeySetValid
            SC_KeyM_Certificate_VerifyCertWithBackendCert: operation=KeyM_Certificate.VerifyCertWithBackendCert
            SC_SecLog_SuccessfulAuthAndEnhanceRights_SuccessfulAuthAndEnhanceRights: operation=SecLog_SuccessfulAuthAndEnhanceRights.SuccessfulAuthAndEnhanceRights
            SC_TimeM_RealTime_TimeM_CompareRealTime: operation=TimeM_RealTime.Compare
            SC_TimeM_RealTime_TimeM_GetRealTime: operation=TimeM_RealTime.Get
            SC_TimeM_RealTime_TimeM_SetRealTime: operation=TimeM_RealTime.Set
            SC_SsaCdd_Csm_SignatureVerify: operation=SsaCdd_Csm.SignatureVerify
        Ssa_RightsM_RoutineServices_Routine_Enhance_Access_Rights_Start: can-enter-exclusive-area=RightsM_ExclusiveArea
          sync call SC_CertP_Functions_AttributeCertificate_Parse: operation=CertP_Functions.AttributeCertificate_Parse
          sync call SC_KeyM_Certificate_VerifyCertWithBackendCert: operation=KeyM_Certificate.VerifyCertWithBackendCert
          sync call SC_SecLog_SuccessfulAuthAndEnhanceRights_SuccessfulAuthAndEnhanceRights: operation=SecLog_SuccessfulAuthAndEnhanceRights.SuccessfulAuthAndEnhanceRights
        Ssa_RightsM_RoutineServices_Routine_Synchronize_Secured_System_Date_and_Time_Start: can-enter-exclusive-area=RightsM_ExclusiveArea
          sync call SC_CsmRandomGenerate_RandomGenerate: operation=CsmRandomGenerate.RandomGenerate
          sync call SC_NvMService_Nonce_SetRamBlockStatus: operation=NvMService_RightsM_Nonce.SetRamBlockStatus
          sync call SC_TimeM_TickCount_Get: operation=TimeM_TickCount.Get
        Ssa_RightsM_SecurityAccess_CompareKey: can-enter-exclusive-area=RightsM_ExclusiveArea
          data-send-points:
            access SEND_RightsM_SecurityLevelChange_currentLevel: accessed-variable=RightsM_SecurityLevelChange.currentLevel
          sync call SC_SecLog_AuthorizationBySecurityAccess_AuthorizationBySecurityAccess: operation=SecLog_AuthorizationBySecurityAccess.AuthorizationBySecurityAccess
          sync call SC_SsaCdd_Csm_SignatureVerify: operation=SsaCdd_Csm.SignatureVerify
        Ssa_RightsM_SecurityAccess_GetSeed
          sync call SC_CsmRandomGenerate_RandomGenerate: operation=CsmRandomGenerate.RandomGenerate
        Ssa_RightsM_ServiceRequestNotification_Confirmation: can-enter-exclusive-area=RightsM_ExclusiveArea
          5 x sync call:
            SC_SecLog_SuccessfulDiagServiceExecutionEvent_ActivateDebugIf_SuccessfulDiagServiceExecution: operation=SecLog_SuccessfulDiagServiceExecutionEvent_ActivateDebugIf.SuccessfulDiagServiceExecution
            SC_SecLog_SuccessfulDiagServiceExecutionEvent_ClearSarMemory_SuccessfulDiagServiceExecution: operation=SecLog_SuccessfulDiagServiceExecutionEvent_ClearSarMemory.SuccessfulDiagServiceExecution
            SC_SecLog_SuccessfulDiagServiceExecutionEvent_EnableSarMemOverwrite_SuccessfulDiagServiceExecution: operation=SecLog_SuccessfulDiagServiceExecutionEvent_EnableSarMemOverwrite.SuccessfulDiagServiceExecution
            SC_SecLog_SuccessfulDiagServiceExecutionEvent_EraseMemory_SuccessfulDiagServiceExecution: operation=SecLog_SuccessfulDiagServiceExecutionEvent_EraseMemory.SuccessfulDiagServiceExecution
            SC_SecLog_AuthorizationBySecurityAccess_AuthorizationBySecurityAccess: operation=SecLog_AuthorizationBySecurityAccess.AuthorizationBySecurityAccess
        Ssa_RightsM_ServiceRequestNotification_Indication: can-enter-exclusive-area=RightsM_ExclusiveArea
          sync call SC_SecLog_RightsManagementEvent_RightsManagement_1: operation=SecLog_RightsManagementEvent.RightsManagement
        Ssa_RightsM_DiagnosticChannel_GetDiagnosticUserRole: can-enter-exclusive-area=RightsM_ExclusiveArea, can-be-invoked-concurrently=true
        Ssa_RightsM_DiagnosticChannel_GetPostProductionStatus: can-be-invoked-concurrently=true
        Ssa_RightsM_RoutineServices_Status_of_Post_Production_Flag_RequestResults
        Ssa_RightsM_RoutineServices_Status_of_Post_Production_Flag_Start
          sync call SC_NvMService_RightsM_PostProductionStatus_GetErrorStatus: operation=NvMService_RightsM_PostProductionStatus.GetErrorStatus
          sync call SC_NvMService_RightsM_PostProductionStatus_WriteBlock: operation=NvMService_RightsM_PostProductionStatus.WriteBlock
        Ssa_RightsM_RoutineServices_Status_of_Post_Production_Flag_Stop
      swc service dependency NvM_RightsM_AclVersion
        assigned-datas:
          role=ramBlock, used-data-element=RightsMAclVersion
          role=defaultValue, used-parameter-element=NvM_RightsM_AclVersion_DefaultValue
        service-needs:
          nv block needs NvM_RightsM_AclVersion: ram-block-status-control=API, restore-at-start=true, store-at-shutdown=false
      swc service dependency NvM_RightsM_Nonce
        assigned-datas:
          role=ramBlock, used-data-element=RightsMNonce
          role=defaultValue, used-parameter-element=NvM_RightsM_Nonce_DefaultValue
        service-needs:
          nv block needs NvM_RightsM_Nonce: ram-block-status-control=API, restore-at-start=true, store-at-shutdown=false
      swc service dependency NvM_RightsM_PostProductionStatus
        assigned-datas:
          role=ramBlock, used-data-element=RightsMPostProductionStatus
          role=defaultValue, used-parameter-element=NvM_RightsM_PostProductionStatus_DefaultValue
        service-needs:
          nv block needs NvM_RightsM_PostProductionStatus: n-data-sets=0, ram-block-status-control=API, reliability=NO-PROTECTION, restore-at-start=true, store-at-shutdown=false
      shared-parameters:
        parameter data prototype NvM_RightsM_AclVersion_DefaultValue: type=SecLog_AclVersionType, init-value=constant-reference=Ssa_Init_Zero_11Byte
        parameter data prototype NvM_RightsM_Nonce_DefaultValue: type=RightsM_NonceType, init-value=constant-reference=Ssa_RightM_NonceInit
        parameter data prototype NvM_RightsM_PostProductionStatus_DefaultValue: type=Ssa_PostProductionStatusType, init-value=SSA_POST_PRODUCTION_STATUS_DEACTIVATED
  swc implementation Ssa_RightsM_Implementation: behavior=Ssa_RightsM_InternalBehavior
    code-descriptors:
      code Default: artifact-descriptors=autosar-engineering-object=category=SWSRC
